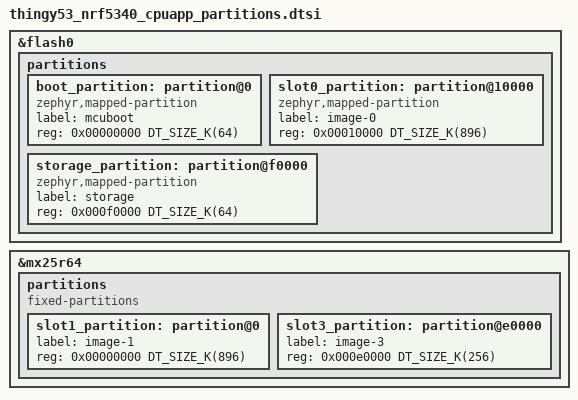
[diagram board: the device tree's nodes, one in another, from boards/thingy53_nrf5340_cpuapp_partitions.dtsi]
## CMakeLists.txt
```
#
# Copyright (c) 2022 Nordic Semiconductor ASA
#
# SPDX-License-Identifier: LicenseRef-Nordic-5-Clause
#

cmake_minimum_required(VERSION 3.20.0)

find_package(Zephyr REQUIRED HINTS $ENV{ZEPHYR_BASE})
project(nrf_wifi_radio_test)

target_sources(app PRIVATE
  src/nrf_wifi_radio_test_main.c
)
```

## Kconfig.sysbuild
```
#
# Copyright (c) 2024 Nordic Semiconductor
#
# SPDX-License-Identifier: LicenseRef-Nordic-5-Clause
#

source "${ZEPHYR_NRF_MODULE_DIR}/samples/wifi/Kconfig.sysbuild.nrf70"

config SUPPORT_NETCORE_PERIPHERAL_RADIO_TEST
	bool
	default y if SOC_SERIES_NRF53 || SOC_SERIES_NRF54

choice NETCORE

config NETCORE_PERIPHERAL_RADIO_TEST
	bool "peripheral_radio_test"
	depends on SUPPORT_NETCORE_PERIPHERAL_RADIO_TEST
	help
	  Include peripheral_radio_test as the netcore image to use

endchoice

config NETCORE_IMAGE_NAME
	default "peripheral_radio_test" if NETCORE_PERIPHERAL_RADIO_TEST

config NETCORE_IMAGE_PATH
	default "$(ZEPHYR_NRF_MODULE_DIR)/samples/peripheral/radio_test/" if NETCORE_PERIPHERAL_RADIO_TEST

source "share/sysbuild/Kconfig"
```

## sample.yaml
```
sample:
  description: Wi-Fi radio test sample application
  name: Wi-Fi radio test
tests:
  sample.nrf7002.radio_test:
    sysbuild: true
    build_only: true
    integration_platforms:
      - nrf7002dk/nrf5340/cpuapp
    platform_allow: nrf7002dk/nrf5340/cpuapp
    tags:
      - ci_build
      - sysbuild
      - ci_samples_wifi
  sample.nrf7001.radio_test:
    sysbuild: true
    build_only: true
    integration_platforms:
      - nrf7002dk/nrf5340/cpuapp/nrf7001
    platform_allow: nrf7002dk/nrf5340/cpuapp/nrf7001
    tags:
      - ci_build
      - sysbuild
      - ci_samples_wifi
    skip: true
  sample.nrf7002.radio_test_combo:
    sysbuild: true
    build_only: true
    extra_args:
      - CONFIG_NRF70_SR_COEX=y
      - CONFIG_NRF70_SR_COEX_RF_SWITCH=y
      - SB_CONFIG_NETCORE_PERIPHERAL_RADIO_TEST=y
    integration_platforms:
      - nrf7002dk/nrf5340/cpuapp
    platform_allow: nrf7002dk/nrf5340/cpuapp
    tags:
      - ci_build
      - sysbuild
      - ci_samples_wifi
  sample.nrf7002_eks.radio_test:
    sysbuild: true
    build_only: true
    extra_args: SHIELD=nrf7002ek
    integration_platforms:
      - nrf5340dk/nrf5340/cpuapp
    platform_allow:
      - nrf5340dk/nrf5340/cpuapp
      - nrf52840dk/nrf52840
    tags:
      - ci_build
      - sysbuild
      - ci_samples_wifi
  sample.nrf7001_eks.radio_test:
    sysbuild: true
    build_only: true
    extra_args: SHIELD=nrf7002ek_nrf7001
    integration_platforms:
      - nrf52840dk/nrf52840
    platform_allow:
      - nrf5340dk/nrf5340/cpuapp
      - nrf52840dk/nrf52840
    tags:
      - ci_build
      - sysbuild
      - ci_samples_wifi
  sample.nrf7000_eks.radio_test:
    sysbuild: true
    build_only: true
    extra_args: SHIELD=nrf7002ek_nrf7000
    integration_platforms:
      - nrf9160dk/nrf9160/ns
    platform_allow: nrf9160dk/nrf9160/ns
    tags:
      - ci_build
      - sysbuild
      - ci_samples_wifi
  sample.nrf7002_eb.thingy53.radio_test:
    sysbuild: true
    build_only: true
    extra_args: multi_domain_SHIELD=nrf7002eb
    integration_platforms:
      - thingy53/nrf5340/cpuapp
    platform_allow: thingy53/nrf5340/cpuapp
    tags:
      - ci_build
      - sysbuild
      - ci_samples_wifi
  sample.thingy91x_nrf7002.radio_test:
    sysbuild: true
    build_only: true
    platform_allow: thingy91x/nrf9151/ns
    tags:
      - ci_build
      - sysbuild
      - ci_samples_wifi
  sample.nrf54h_nrf7002eb.radio_test:
    sysbuild: true
    build_only: true
    extra_args:
      - multi_domain_SHIELD="nrf7002eb_interposer_p1;nrf7002eb"
      - SNIPPET=nrf70-wifi
      - CONFIG_SOC_NRF54H20_CPURAD_ENABLE=y
      - SB_CONFIG_NETCORE_PERIPHERAL_RADIO_TEST=y
    integration_platforms:
      - nrf54h20dk/nrf54h20/cpuapp
    platform_allow:
      - nrf54h20dk/nrf54h20/cpuapp
    tags:
      - ci_build
      - sysbuild
      - ci_samples_wifi
  sample.nrf7120.radio_test:
    sysbuild: true
    build_only: true
    extra_args:
      - SB_CONFIG_WIFI_NRF70=n
    integration_platforms:
      - nrf7120dk/nrf7120/cpuapp
    platform_allow: nrf7120dk/nrf7120/cpuapp
    tags:
      - ci_build
      - sysbuild
      - ci_samples_nrf71_wifi
```

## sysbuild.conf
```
#
# Copyright (c) 2024 Nordic Semiconductor ASA
#
# SPDX-License-Identifier: LicenseRef-Nordic-5-Clause
#

SB_CONFIG_WIFI_NRF70_RADIO_TEST=y
```

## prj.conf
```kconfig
#
# Copyright (c) 2022 Nordic Semiconductor ASA
#
# SPDX-License-Identifier: LicenseRef-Nordic-5-Clause
#
CONFIG_WIFI=y

#CONFIG_INIT_STACKS=y

# Memories
CONFIG_MAIN_STACK_SIZE=5200
CONFIG_SHELL_STACK_SIZE=5200
#64K memory needed for IQ sample captures.
CONFIG_NRF_WIFI_CTRL_HEAP_SIZE=78304

# Debugging
CONFIG_STACK_SENTINEL=y
CONFIG_DEBUG_COREDUMP=y
CONFIG_DEBUG_COREDUMP_BACKEND_LOGGING=y
CONFIG_DEBUG_COREDUMP_MEMORY_DUMP_MIN=y
CONFIG_SHELL_CMDS_RESIZE=n
#CONFIG_DEBUG=y

# Logging
CONFIG_LOG=y
CONFIG_PRINTK=y
CONFIG_SHELL=y
CONFIG_SHELL_GETOPT=y
CONFIG_DEVICE_SHELL=y
CONFIG_POSIX_TIMERS=y
CONFIG_DATE_SHELL=y
CONFIG_LOG_BUFFER_SIZE=4096
CONFIG_SHELL_BACKEND_SERIAL_RX_RING_BUFFER_SIZE=1024
```

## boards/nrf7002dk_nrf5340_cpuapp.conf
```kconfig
# Copyright (c) 2026 Nordic Semiconductor ASA
#
# SPDX-License-Identifier: LicenseRef-Nordic-5-Clause

CONFIG_NRF70_RADIO_TEST=y
CONFIG_NRF70_SR_COEX=y
```

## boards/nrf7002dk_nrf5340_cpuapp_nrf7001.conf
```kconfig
#
# Copyright (c) 2026 Nordic Semiconductor ASA
#
# SPDX-License-Identifier: LicenseRef-Nordic-5-Clause
#

#NRF70 specific configuration
CONFIG_NRF70_RADIO_TEST=y
CONFIG_NRF70_SR_COEX=y
```

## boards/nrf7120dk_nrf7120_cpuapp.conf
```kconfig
# Copyright (c) 2026 Nordic Semiconductor ASA
#
# SPDX-License-Identifier: LicenseRef-Nordic-5-Clause

CONFIG_NRF71_RADIO_TEST=y
CONFIG_NRF71_SR_COEX=y
CONFIG_HEAP_MEM_POOL_SIZE=65536
```

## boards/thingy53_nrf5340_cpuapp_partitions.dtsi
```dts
/*
 * Copyright (c) 2024 Nordic Semiconductor ASA
 *
 * SPDX-License-Identifier: LicenseRef-Nordic-5-Clause
 */

/*
 * Shared flash partition layout for thingy53/nrf5340/cpuapp.
 * Used by the sysbuild mcuboot overlay.
 *
 * Internal flash (flash0):
 *   boot_partition    @ 0x000000  64 KB  MCUboot
 *   slot0_partition   @ 0x010000 896 KB  Image 0 primary
 *   storage_partition @ 0x0f0000  64 KB  Settings
 *
 * External QSPI flash (mx25r64):
 *   slot1_partition   @ 0x000000 896 KB  Image 0 secondary
 *   slot3_partition   @ 0x0e0000 256 KB  Image 1 secondary (network core)
 */

/delete-node/ &boot_partition;
/delete-node/ &slot0_partition;
/delete-node/ &slot1_partition;
/delete-node/ &storage_partition;

&flash0 {
	partitions {
		ranges;
		#address-cells = <1>;
		#size-cells = <1>;

		boot_partition: partition@0 {
			compatible = "zephyr,mapped-partition";
			label = "mcuboot";
			reg = <0x00000000 DT_SIZE_K(64)>;
		};

		slot0_partition: partition@10000 {
			compatible = "zephyr,mapped-partition";
			label = "image-0";
			reg = <0x00010000 DT_SIZE_K(896)>;
		};

		storage_partition: partition@f0000 {
			compatible = "zephyr,mapped-partition";
			label = "storage";
			reg = <0x000f0000 DT_SIZE_K(64)>;
		};
	};
};

&mx25r64 {
	status = "okay";

	partitions {
		compatible = "fixed-partitions";
		#address-cells = <1>;
		#size-cells = <1>;

		slot1_partition: partition@0 {
			label = "image-1";
			reg = <0x00000000 DT_SIZE_K(896)>;
		};

		slot3_partition: partition@e0000 {
			label = "image-3";
			reg = <0x000e0000 DT_SIZE_K(256)>;
		};
	};
};
```

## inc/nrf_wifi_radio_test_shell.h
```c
/*
 * Copyright (c) 2022 Nordic Semiconductor ASA
 *
 * SPDX-License-Identifier: LicenseRef-Nordic-5-Clause
 */

/* @file
 * @brief nRF Wi-Fi radio-test mode shell module
 */

#include <zephyr/kernel.h>
#include <stdio.h>
#include <stdlib.h>
#include <zephyr/shell/shell.h>
#include <zephyr/init.h>
#include <ctype.h>
#ifndef CONFIG_NRF71_RADIO_TEST
#include <host_rpu_sys_if.h>
#endif
#include <radio_test/fmac_structs.h>
#include <zephyr/drivers/wifi/nrf_wifi/bus/rpu_hw_if.h>

enum nrf_wifi_frequency_bands {
	NRF_WIFI_FREQ_BAND_2_4_GHZ = 0,
	NRF_WIFI_FREQ_BAND_5_GHZ,
	NRF_WIFI_FREQ_BAND_6_GHZ,
};

/* RX capture display constants */
#define SAMPLES_PER_LINE 16
#define BYTES_PER_SAMPLE 3
#define BYTES_PER_LINE 48

struct nrf_wifi_ctx_zep_rt {
	struct nrf_wifi_fmac_priv *fmac_priv;
	struct rpu_conf_params conf_params;
};
```

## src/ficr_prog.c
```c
/*
 * Copyright (c) 2024 Nordic Semiconductor ASA
 *
 * SPDX-License-Identifier: LicenseRef-Nordic-5-Clause
 */

/* @file
 * @brief NRF Wi-Fi radio FICR programming functions
 */

#include <zephyr/logging/log.h>
#include <zephyr/kernel.h>
#include <zephyr/drivers/wifi/nrf_wifi/bus/rpu_hw_if.h>

#include "common/rpu_if.h"
#include "ficr_prog.h"


LOG_MODULE_DECLARE(otp_prog, CONFIG_WIFI_LOG_LEVEL);

static void write_word(unsigned int addr, unsigned int data)
{
	rpu_write(addr, &data, 4);
}

static void read_word(unsigned int addr, unsigned int *data)
{
	rpu_read(addr, data, 4);
}

unsigned int check_protection(unsigned int *buff, unsigned int off1, unsigned int off2,
		    unsigned int off3, unsigned int off4)
{
	if ((buff[off1] == OTP_PROGRAMMED) &&
		(buff[off2] == OTP_PROGRAMMED)  &&
		(buff[off3] == OTP_PROGRAMMED) &&
		(buff[off4] == OTP_PROGRAMMED)) {
		return OTP_PROGRAMMED;
	} else if ((buff[off1] == OTP_FRESH_FROM_FAB) &&
		(buff[off2] == OTP_FRESH_FROM_FAB) &&
		(buff[off3] == OTP_FRESH_FROM_FAB) &&
		(buff[off4] == OTP_FRESH_FROM_FAB)) {
		return OTP_FRESH_FROM_FAB;
	} else if ((buff[off1] == OTP_ENABLE_PATTERN) &&
		(buff[off2] == OTP_ENABLE_PATTERN) &&
		(buff[off3] == OTP_ENABLE_PATTERN) &&
		(buff[off4] == OTP_ENABLE_PATTERN)) {
		return OTP_ENABLE_PATTERN;
	} else {
		return OTP_INVALID;
	}
}

static void set_otp_timing_reg_40mhz(void)
{
	write_word(OTP_TIMING_REG1_ADDR, OTP_TIMING_REG1_VAL);
	write_word(OTP_TIMING_REG2_ADDR, OTP_TIMING_REG2_VAL);
}

static int poll_otp_ready(void)
{
	int otp_mem_status = 0;
	int poll = 0;

	while (poll != 100) {
		read_word(OTP_POLL_ADDR, &otp_mem_status);

		if ((otp_mem_status & OTP_READY) == OTP_READY) {
			return 0;
		}
		poll++;
	}
	LOG_ERR("OTP is not ready");
	return -ENOEXEC;
}

static int req_otp_standby_mode(void)
{
	write_word(OTP_RWSBMODE_ADDR, 0x0);
	return poll_otp_ready();
}

static int otp_wr_voltage_2v5(void)
{
	int err;

	err = req_otp_standby_mode();

	if (err) {
		LOG_ERR("Failed Setting OTP voltage IOVDD to 2.5V");
		return -ENOEXEC;
	}
	write_word(OTP_VOLTCTRL_ADDR, OTP_VOLTCTRL_2V5);
	return 0;
}

static int poll_otp_read_valid(void)
{
	int otp_mem_status = 0;
	int poll = 0;

	while (poll < 100) {
		read_word(OTP_POLL_ADDR, &otp_mem_status);

		if ((otp_mem_status & OTP_READ_VALID) == OTP_READ_VALID) {
			return 0;
		}
		poll++;
	}
	LOG_ERR("%s: OTP read failed", __func__);
	return -ENOEXEC;
}

static int poll_otp_wrdone(void)
{
	int otp_mem_status = 0;
	int poll = 0;

	while (poll < 100) {
		read_word(OTP_POLL_ADDR, &otp_mem_status);

		if ((otp_mem_status & OTP_WR_DONE) == OTP_WR_DONE) {
			return 0;
		}
		poll++;
	}
	LOG_ERR("%s: OTP write done failed", __func__);
	return -ENOEXEC;
}

static int req_otp_read_mode(void)
{
	write_word(OTP_RWSBMODE_ADDR, OTP_READ_MODE);
	return poll_otp_ready();
}

static int req_otp_byte_write_mode(void)
{
	write_word(OTP_RWSBMODE_ADDR, OTP_BYTE_WRITE_MODE);
	return poll_otp_ready();
}

static unsigned int read_otp_location(unsigned int offset, unsigned int *read_val)
{
	int err;

	write_word(OTP_RDENABLE_ADDR,  offset);
	err = poll_otp_read_valid();
	if (err) {
		LOG_ERR("OTP read failed");
		return err;
	}
	read_word(OTP_READREG_ADDR, read_val);

	return 0;
}

static int  write_otp_location(unsigned int otp_location_offset, unsigned int otp_data)
{
	write_word(OTP_WRENABLE_ADDR,  otp_location_offset);
	write_word(OTP_WRITEREG_ADDR,  otp_data);

	return poll_otp_wrdone();
}

static int otp_rd_voltage_1v8(void)
{
	int err;

	err = req_otp_standby_mode();
	if (err) {
		LOG_ERR("error in %s", __func__);
		return err;
	}
	write_word(OTP_VOLTCTRL_ADDR, OTP_VOLTCTRL_1V8);

	return 0;
}

static int update_mac_addr(unsigned int index, unsigned int *write_val)
{
	int ret = 0;

	for (int i = 0; i < 2; i++) {
		ret = write_otp_location(MAC0_ADDR + 2 * index + i, write_val[i]);
		if (ret == -ENOEXEC) {
			LOG_ERR("FICR: Failed to update MAC ADDR%d", index);
			break;
		}
		LOG_INF("mac addr %d : Reg%d (0x%x) = 0x%04x",
					index, (i+1), (MAC0_ADDR + i) << 2, write_val[i]);
	}
	return ret;
}

int write_otp_memory(unsigned int otp_addr, unsigned int *write_val)
{
	int err = 0;
	int	mask_val;
	int ret = 0;
	int retrim_loc = 0;

	err = poll_otp_ready();
	if (err) {
		LOG_ERR("err in otp ready poll");
		return err;
	}

	set_otp_timing_reg_40mhz();

	err = otp_wr_voltage_2v5();
	if (err) {
		LOG_ERR("error in write_voltage 2v5");
		goto _exit_otp_write;
	}

	err = req_otp_byte_write_mode();
	if (err) {
		LOG_ERR("error in OTP byte write mode");
		goto _exit_otp_write;
	}

	switch (otp_addr) {
	case REGION_PROTECT:
		write_otp_location(REGION_PROTECT, write_val[0]);
		write_otp_location(REGION_PROTECT+1, write_val[0]);
		write_otp_location(REGION_PROTECT+2, write_val[0]);
		write_otp_location(REGION_PROTECT+3, write_val[0]);

		LOG_INF("Written REGION_PROTECT0 (0x%x) : 0x%04x",
						(REGION_PROTECT << 2), write_val[0]);
		LOG_INF("Written REGION_PROTECT1 (0x%x) : 0x%04x",
						(REGION_PROTECT+1) << 2, write_val[0]);
		LOG_INF("Written REGION_PROTECT2 (0x%x) : 0x%04x",
						(REGION_PROTECT+2) << 2, write_val[0]);
		LOG_INF("Written REGION_PROTECT3 (0x%x) : 0x%04x",
						(REGION_PROTECT+3) << 2, write_val[0]);
		break;
	case QSPI_KEY:
		mask_val = QSPI_KEY_FLAG_MASK;
		for (int i = 0; i < QSPI_KEY_LENGTH_BYTES / 4; i++) {
			ret = write_otp_location(QSPI_KEY + i, write_val[i]);
			if (ret == -ENOEXEC) {
				LOG_ERR("FICR: Failed to write QSPI key offset-%d", QSPI_KEY + i);
				goto _exit_otp_write;
			}
			LOG_INF("Written QSPI_KEY0 (0x%x) : 0x%04x",
						(QSPI_KEY + i) << 2, write_val[i]);
		}
		write_otp_location(REGION_DEFAULTS, mask_val);
		LOG_INF("Written REGION_DEFAULTS (0x%x) : 0x%04x",
						(REGION_DEFAULTS) << 2, mask_val);
		break;
	case MAC0_ADDR:
		mask_val = MAC0_ADDR_FLAG_MASK;
		ret = update_mac_addr(0, write_val);
		if (ret == -ENOEXEC) {
			goto _exit_otp_write;
		}

		write_otp_location(REGION_DEFAULTS, mask_val);
		LOG_INF("Written MAC address 0");
		LOG_INF("Written REGION_DEFAULTS (0x%x) : 0x%04x",
						(REGION_DEFAULTS) << 2, mask_val);
		break;
	case MAC1_ADDR:
		mask_val = MAC1_ADDR_FLAG_MASK;
		ret = update_mac_addr(1, write_val);
		if (ret == -ENOEXEC) {
			goto _exit_otp_write;
		}
		write_otp_location(REGION_DEFAULTS, mask_val);
		LOG_INF("Written MAC address 1");
		LOG_INF("Written REGION_DEFAULTS (0x%x) : 0x%04x",
						(REGION_DEFAULTS) << 2, mask_val);
		break;
	case CALIB_XO:
		mask_val = CALIB_XO_FLAG_MASK;
		ret = write_otp_location(CALIB_XO, write_val[0]);

		if (ret == -ENOEXEC) {
			LOG_ERR("XO_Update Exception");
			goto _exit_otp_write;
		} else {
			write_otp_location(REGION_DEFAULTS, mask_val);

			LOG_INF("Written CALIB_XO (0x%x) to 0x%04x",
						CALIB_XO << 2, write_val[0]);
			LOG_INF("Written REGION_DEFAULTS (0x%x) : 0x%04x",
						(REGION_DEFAULTS) << 2, mask_val);
		}
		break;
	case PRODRETEST_PROGVERSION:
		ret = write_otp_location(PRODRETEST_PROGVERSION, *write_val);

		if (ret == -ENOEXEC) {
			LOG_ERR("PRODRETEST.PROGVERSION_Update Exception");
			goto _exit_otp_write;
		} else {
			LOG_INF("Written PRODRETEST.PROGVERSION 0x%04x", *write_val);
		}
		break;
	case PRODRETEST_TRIM0:
	case PRODRETEST_TRIM1:
	case PRODRETEST_TRIM2:
	case PRODRETEST_TRIM3:
	case PRODRETEST_TRIM4:
	case PRODRETEST_TRIM5:
	case PRODRETEST_TRIM6:
	case PRODRETEST_TRIM7:
	case PRODRETEST_TRIM8:
	case PRODRETEST_TRIM9:
	case PRODRETEST_TRIM10:
	case PRODRETEST_TRIM11:
	case PRODRETEST_TRIM12:
	case PRODRETEST_TRIM13:
	case PRODRETEST_TRIM14:
		retrim_loc = otp_addr - PRODRETEST_TRIM0;
		ret = write_otp_location(otp_addr, *write_val);

		if (ret == -ENOEXEC) {
			LOG_ERR("PRODRETEST.TRIM_Update Exception");
			goto _exit_otp_write;
		} else {
			LOG_INF("Written PRODRETEST.TRIM%d 0x%04x",
						retrim_loc, *write_val);
		}
		break;
	case REGION_DEFAULTS:
		write_otp_location(REGION_DEFAULTS, write_val[0]);

		LOG_INF("Written REGION_DEFAULTS (0x%x) to 0x%04x",
						REGION_DEFAULTS << 2, write_val[0]);
		break;
	default:
		LOG_ERR("unknown field received: %d", otp_addr);

	}
	return ret;

_exit_otp_write:
	err  = req_otp_standby_mode();
	err |= otp_rd_voltage_1v8();
	return err;
}

int read_otp_memory(unsigned int otp_addr, unsigned int *read_val, int len)
{
	int	err;

	err = poll_otp_ready();
	if (err) {
		LOG_ERR("err in otp ready poll");
		return -ENOEXEC;
	}

	set_otp_timing_reg_40mhz();

	err = otp_rd_voltage_1v8();
	if (err) {
		LOG_ERR("error in read_voltage 1v8");
		return -ENOEXEC;
	}

	err = req_otp_read_mode();
	if (err) {
		LOG_ERR("error in req_otp_read_mode()");
		return -ENOEXEC;
	}

	for (int i = 0; i < len; i++) {
		read_otp_location(otp_addr + i, &read_val[i]);
	}

	return req_otp_standby_mode();
}
```

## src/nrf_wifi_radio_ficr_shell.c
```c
/*
 * Copyright (c) 2022 Nordic Semiconductor ASA
 *
 * SPDX-License-Identifier: LicenseRef-Nordic-5-Clause
 */

/* @file
 * @brief NRF Wi-Fi radio test shell module
 */

#include <zephyr/logging/log.h>
#include <fmac_main.h>
#include <util.h>
#include <nrf_wifi_radio_test_shell.h>
#include "ficr_prog.h"

#include "common/fmac_api_common.h"

extern struct nrf_wifi_drv_priv_zep rpu_drv_priv_zep;
static struct nrf_wifi_ctx_zep *ctx = &rpu_drv_priv_zep.rpu_ctx_zep;

LOG_MODULE_REGISTER(otp_prog, CONFIG_WIFI_LOG_LEVEL);

static void disp_location_status(const struct shell *shell, char *region, unsigned int ret)
{
	switch (ret) {

	case OTP_PROGRAMMED:
		shell_fprintf(shell, SHELL_INFO, "%s Region is locked!!!\n", region);
		break;
	case OTP_ENABLE_PATTERN:
		shell_fprintf(shell, SHELL_INFO, "%s Region is open for R/W\n", region);
		break;
	case OTP_FRESH_FROM_FAB:
		shell_fprintf(shell, SHELL_INFO,
				"%s Region is unprogrammed - program to enable R/W\n", region);
		break;
	default:
		shell_fprintf(shell, SHELL_ERROR, "%s Region is in invalid state\n", region);
		break;
	}
	shell_fprintf(shell, SHELL_INFO, "\n");
}

static void disp_fields_status(const struct shell *shell, unsigned int flags)
{
	if (flags & (~QSPI_KEY_FLAG_MASK)) {
		shell_fprintf(shell, SHELL_INFO, "QSPI Keys are not programmed in OTP\n");
	} else {
		shell_fprintf(shell, SHELL_INFO, "QSPI Keys are programmed in OTP\n");
	}

	if (flags & (~MAC0_ADDR_FLAG_MASK)) {
		shell_fprintf(shell, SHELL_INFO, "MAC0 Address are not programmed in OTP\n");
	} else {
		shell_fprintf(shell, SHELL_INFO, "MAC0 Address is programmed in OTP\n");
	}

	if (flags & (~MAC1_ADDR_FLAG_MASK)) {
		shell_fprintf(shell, SHELL_INFO, "MAC1 Address are not programmed in OTP\n");
	} else {
		shell_fprintf(shell, SHELL_INFO, "MAC1 Address is programmed in OTP\n");
	}

	if (flags & (~CALIB_XO_FLAG_MASK)) {
		shell_fprintf(shell, SHELL_INFO, "CALIB_XO is not programmed in OTP\n");
	} else {
		shell_fprintf(shell, SHELL_INFO, "CALIB_XO is programmed in OTP\n");
	}
}


static int nrf_wifi_radio_test_otp_get_status(const struct shell *shell,
					size_t argc,
					char  *argv[])
{
	unsigned int ret, err;
	unsigned int val[OTP_MAX_WORD_LEN];

	/* read all the OTP memory */
	err = read_otp_memory(0, &val[0], OTP_MAX_WORD_LEN);
	if (err) {
		shell_fprintf(shell, SHELL_ERROR, "FAILED reading otp memory......\n");
		return -ENOEXEC;
	}

	shell_fprintf(shell, SHELL_INFO, "Checking OTP PROTECT Region......\n");
	ret = check_protection(&val[0], REGION_PROTECT, REGION_PROTECT + 1,
							REGION_PROTECT + 2, REGION_PROTECT + 3);

	disp_location_status(shell, "OTP", ret);
	disp_fields_status(shell, val[REGION_DEFAULTS]);

	return 0;
}

static int nrf_wifi_radio_test_otp_read_params(const struct shell *shell,
					size_t argc,
					char  *argv[])
{
	unsigned int val[OTP_MAX_WORD_LEN];
	unsigned int ret, err;

	err = read_otp_memory(0, &val[0], OTP_MAX_WORD_LEN);
	if (err) {
		shell_fprintf(shell, SHELL_ERROR, "FAILED reading otp memory......\n");
		return -ENOEXEC;
	}

	ret = check_protection(&val[0], REGION_PROTECT + 0, REGION_PROTECT + 1,
							REGION_PROTECT + 2, REGION_PROTECT + 3);
	disp_location_status(shell, "OTP", ret);

	shell_fprintf(shell, SHELL_INFO, "PRODTEST.FT.PROGVERSION = 0x%08x\n",
		val[PRODTEST_FT_PROGVERSION]);
	shell_fprintf(shell, SHELL_INFO, "\n");

	shell_fprintf(shell, SHELL_INFO, "PRODTEST.TRIM0 = 0x%08x\n", val[PRODTEST_TRIM0]);
	shell_fprintf(shell, SHELL_INFO, "PRODTEST.TRIM1 = 0x%08x\n", val[PRODTEST_TRIM1]);
	shell_fprintf(shell, SHELL_INFO, "PRODTEST.TRIM2 = 0x%08x\n", val[PRODTEST_TRIM2]);
	shell_fprintf(shell, SHELL_INFO, "PRODTEST.TRIM3 = 0x%08x\n", val[PRODTEST_TRIM3]);
	shell_fprintf(shell, SHELL_INFO, "PRODTEST.TRIM4 = 0x%08x\n", val[PRODTEST_TRIM4]);
	shell_fprintf(shell, SHELL_INFO, "PRODTEST.TRIM5 = 0x%08x\n", val[PRODTEST_TRIM5]);
	shell_fprintf(shell, SHELL_INFO, "PRODTEST.TRIM6 = 0x%08x\n", val[PRODTEST_TRIM6]);
	shell_fprintf(shell, SHELL_INFO, "PRODTEST.TRIM7 = 0x%08x\n", val[PRODTEST_TRIM7]);
	shell_fprintf(shell, SHELL_INFO, "PRODTEST.TRIM8 = 0x%08x\n", val[PRODTEST_TRIM8]);
	shell_fprintf(shell, SHELL_INFO, "PRODTEST.TRIM9 = 0x%08x\n", val[PRODTEST_TRIM9]);
	shell_fprintf(shell, SHELL_INFO, "PRODTEST.TRIM10 = 0x%08x\n",
		val[PRODTEST_TRIM10]);
	shell_fprintf(shell, SHELL_INFO, "PRODTEST.TRIM11 = 0x%08x\n",
		val[PRODTEST_TRIM11]);
	shell_fprintf(shell, SHELL_INFO, "PRODTEST.TRIM12 = 0x%08x\n",
		val[PRODTEST_TRIM12]);
	shell_fprintf(shell, SHELL_INFO, "PRODTEST.TRIM13 = 0x%08x\n",
		val[PRODTEST_TRIM13]);
	shell_fprintf(shell, SHELL_INFO, "PRODTEST.TRIM14 = 0x%08x\n",
		val[PRODTEST_TRIM14]);
	shell_fprintf(shell, SHELL_INFO, "\n");

	shell_fprintf(shell, SHELL_INFO, "INFO.PART = 0x%08x\n", val[INFO_PART]);
	shell_fprintf(shell, SHELL_INFO, "INFO.VARIANT = 0x%08x\n", val[INFO_VARIANT]);
	shell_fprintf(shell, SHELL_INFO, "\n");

	shell_fprintf(shell, SHELL_INFO, "INFO.UUID0 = 0x%08x\n", val[INFO_UUID + 0]);
	shell_fprintf(shell, SHELL_INFO, "INFO.UUID1 = 0x%08x\n", val[INFO_UUID + 1]);
	shell_fprintf(shell, SHELL_INFO, "INFO.UUID2 = 0x%08x\n", val[INFO_UUID + 2]);
	shell_fprintf(shell, SHELL_INFO, "INFO.UUID3 = 0x%08x\n", val[INFO_UUID + 3]);
	shell_fprintf(shell, SHELL_INFO, "\n");

	shell_fprintf(shell, SHELL_INFO, "REGION.PROTECT0 = 0x%08x\n", val[REGION_PROTECT + 0]);
	shell_fprintf(shell, SHELL_INFO, "REGION.PROTECT1 = 0x%08x\n", val[REGION_PROTECT + 1]);
	shell_fprintf(shell, SHELL_INFO, "REGION.PROTECT2 = 0x%08x\n", val[REGION_PROTECT + 2]);
	shell_fprintf(shell, SHELL_INFO, "REGION.PROTECT3 = 0x%08x\n", val[REGION_PROTECT + 3]);
	shell_fprintf(shell, SHELL_INFO, "\n");

	if (val[REGION_PROTECT + 0] != OTP_FRESH_FROM_FAB) {
		shell_fprintf(shell, SHELL_INFO, "MAC0.ADDRESS0 = 0x%08x\n", val[MAC0_ADDR]);
		shell_fprintf(shell, SHELL_INFO, "MAC0.ADDRESS1 = 0x%08x\n", val[MAC0_ADDR + 1]);
		shell_fprintf(shell, SHELL_INFO, "MAC0.ADDRESS = %02x:%02x:%02x:%02x:%02x:%02x\n",
			(uint8_t)(val[MAC0_ADDR]), (uint8_t)(val[MAC0_ADDR] >> 8),
			(uint8_t)(val[MAC0_ADDR] >> 16), (uint8_t)(val[MAC0_ADDR] >> 24),
			(uint8_t)(val[MAC0_ADDR + 1]), (uint8_t)(val[MAC0_ADDR + 1] >> 8));
		shell_fprintf(shell, SHELL_INFO, "\n");

		shell_fprintf(shell, SHELL_INFO, "MAC1.ADDRESS0 = 0x%08x\n", val[MAC1_ADDR]);
		shell_fprintf(shell, SHELL_INFO, "MAC1.ADDRESS1 = 0x%08x\n", val[MAC1_ADDR + 1]);
		shell_fprintf(shell, SHELL_INFO, "MAC1.ADDRESS = %02x:%02x:%02x:%02x:%02x:%02x\n",
			(uint8_t)(val[MAC1_ADDR]), (uint8_t)(val[MAC1_ADDR] >> 8),
			(uint8_t)(val[MAC1_ADDR] >> 16), (uint8_t)(val[MAC1_ADDR] >> 24),
			(uint8_t)(val[MAC1_ADDR + 1]), (uint8_t)(val[MAC1_ADDR + 1] >> 8));
		shell_fprintf(shell, SHELL_INFO, "\n");

		shell_fprintf(shell, SHELL_INFO, "CALIB.XO = 0x%02x\n", val[CALIB_XO] & 0xFF);

		shell_fprintf(shell, SHELL_INFO, "REGION_DEFAULTS = 0x%08x\n",
			val[REGION_DEFAULTS]);
		shell_fprintf(shell, SHELL_INFO, "\n");
	}
	return 0;
}

static int nrf_wifi_radio_test_otp_read_retrim_version(const struct shell *shell,
					size_t argc,
					char  *argv[])
{
	unsigned int val[1];
	unsigned int err;

	err = read_otp_memory(REGION_PROTECT, &val[0], 1);
	if (err) {
		shell_fprintf(shell, SHELL_ERROR, "FAILED reading otp memory......\n");
		return -ENOEXEC;
	}

	if (val[0] == OTP_FRESH_FROM_FAB) {
		shell_fprintf(shell, SHELL_ERROR,
				"Region is unprogrammed - program to enable R/W\n");
	} else {
		err = read_otp_memory(PRODRETEST_PROGVERSION, &val[0], 1);
		shell_fprintf(shell, SHELL_INFO, "\nPRODRETEST.PROGVERSION = 0x%08x\n",
		val[0]);
		shell_fprintf(shell, SHELL_INFO, "\n");
	}
	return 0;
}

static int nrf_wifi_radio_test_otp_read_retrim_params(const struct shell *shell,
					size_t argc,
					char  *argv[])
{
	unsigned int val[RETRIM_LEN];
	unsigned int err;

	err = read_otp_memory(REGION_PROTECT, val, 1);
	if (err) {
		shell_fprintf(shell, SHELL_ERROR, "FAILED reading otp memory......\n");
		return -ENOEXEC;
	}

	if (val[0] == OTP_FRESH_FROM_FAB) {
		shell_fprintf(shell, SHELL_ERROR,
				"Region is unprogrammed - program to enable R/W\n");
	} else {
		shell_fprintf(shell, SHELL_INFO, "\n");
		err = read_otp_memory(PRODRETEST_TRIM0, val, RETRIM_LEN);
		for (int i = 0; i < RETRIM_LEN; i++) {
			shell_fprintf(shell, SHELL_INFO, "PRODRETEST.TRIM%d = 0x%08x\n", i, val[i]);
		}
		shell_fprintf(shell, SHELL_INFO, "\n");
	}

	return 0;
}

static int nrf_wifi_radio_test_otp_write_params(const struct shell *shell,
					size_t argc,
					char  *argv[])
{
	unsigned int field;
	unsigned int write_val[20];
	unsigned int val[OTP_MAX_WORD_LEN];
	unsigned int ret, err;
	int status = 0;

	if (argc < 2) {
		shell_fprintf(shell, SHELL_ERROR, "invalid # of args : %d\n", argc);
		return -ENOEXEC;
	}

	field  = strtoul(argv[1], NULL, 0);
	/* Align to 32-bit word address */
	field >>= 2;

	if (field < REGION_PROTECT) {
		shell_fprintf(shell, SHELL_ERROR, "INVALID Address 0x%x......\n", field << 2);
		return -ENOEXEC;
	}

	if ((field >= PRODRETEST_PROGVERSION) && (field <= PRODRETEST_TRIM14)) {
		shell_fprintf(shell, SHELL_ERROR, "INVALID Address 0x%x......\n", field << 2);
		return -ENOEXEC;
	}

	err = read_otp_memory(REGION_PROTECT, &val[REGION_PROTECT], 4);
	if (err) {
		shell_fprintf(shell, SHELL_ERROR, "FAILED reading otp memory......\n");
		return -ENOEXEC;
	}

	ret = check_protection(&val[0], REGION_PROTECT, REGION_PROTECT + 1,
						REGION_PROTECT + 2, REGION_PROTECT + 3);
	disp_location_status(shell, "OTP", ret);
	if (ret != OTP_ENABLE_PATTERN && ret != OTP_FRESH_FROM_FAB) {
		shell_fprintf(shell, SHELL_ERROR, "USER Region is not Writeable\n");
		return -ENOEXEC;
	}

	switch (field) {
	case REGION_PROTECT:
		if (argc != 3) {
			shell_fprintf(shell, SHELL_ERROR,
					"invalid # of args for REGION_PROTECT (expected 3) : %d\n",
					argc);
			return -ENOEXEC;
		}
		write_val[0]  = strtoul(argv[2], NULL, 0);
		/* All consecutive 4 words of the REGION_PROTECT are written */
		write_otp_memory(REGION_PROTECT, &write_val[0]);
		break;
	case MAC0_ADDR:
	case MAC1_ADDR:
		struct nrf_wifi_fmac_dev_ctx *fmac_dev_ctx = ctx->rpu_ctx;

		if (!fmac_dev_ctx) {
			shell_fprintf(shell, SHELL_ERROR, "Driver not initialized\n");
			return -ENOEXEC;
		}

		if (argc != 4) {
			shell_fprintf(shell, SHELL_ERROR,
				   "invalid # of args for MAC ADDR write (expected 4) : %d\n",
					argc);
			return -ENOEXEC;
		}
		write_val[0] = strtoul(argv[2], NULL, 0);
		write_val[1] = strtoul(argv[3], NULL, 0) & 0xFFFF;

		if (!nrf_wifi_utils_is_mac_addr_valid((const char *)&write_val[0])) {
			shell_fprintf(shell,
				      SHELL_ERROR,
				      "Invalid MAC address. MAC address cannot be all 0's, broadcast or multicast address\n");
			return -ENOEXEC;
		}

		status = write_otp_memory(field, &write_val[0]);
		break;
	case CALIB_XO:
	case REGION_DEFAULTS:
		if (argc != 3) {
			shell_fprintf(shell, SHELL_ERROR,
			  "invalid # of args for field %d (expected 3) : %d\n", field, argc);
			return -ENOEXEC;
		}
		write_val[0]  = strtoul(argv[2], NULL, 0);
		status = write_otp_memory(field, &write_val[0]);
		break;
	case QSPI_KEY:
		if (argc != 6) {
			shell_fprintf(shell, SHELL_ERROR,
					"invalid # of args for QSPI_KEY (expected 6) : %d\n", argc);
			return -ENOEXEC;
		}
		write_val[0]  = strtoul(argv[2], NULL, 0);
		write_val[1]  = strtoul(argv[3], NULL, 0);
		write_val[2]  = strtoul(argv[4], NULL, 0);
		write_val[3]  = strtoul(argv[5], NULL, 0);
		/* All consecutive 4 words of the qspi keys are written now */
		status = write_otp_memory(QSPI_KEY, &write_val[0]);
		break;
	default:
		shell_fprintf(shell, SHELL_ERROR, "unsupported field %d\n", field);
		return -ENOEXEC;
	}

	if (!status) {
		shell_fprintf(shell, SHELL_INFO, "Finished Writing OTP params\n");
	}

	return 0;
}

static int nrf_wifi_radio_test_otp_write_retrim_version(const struct shell *shell,
					size_t argc,
					char  *argv[])
{
	unsigned int field;
	unsigned int write_val;
	unsigned int val[OTP_MAX_WORD_LEN];
	unsigned int ret, err;
	int status = 0;

	field = PRODRETEST_PROGVERSION;

	if (argc != 2) {
		shell_fprintf(shell, SHELL_ERROR,
		  "invalid # of args for field %d (expected 2) : %d\n", field, argc);
		return -ENOEXEC;
	}

	err = read_otp_memory(REGION_PROTECT, &val[REGION_PROTECT], 4);
	if (err) {
		shell_fprintf(shell, SHELL_ERROR, "FAILED reading otp memory......\n");
		return -ENOEXEC;
	}

	ret = check_protection(&val[0], REGION_PROTECT, REGION_PROTECT + 1,
						REGION_PROTECT + 2, REGION_PROTECT + 3);
	disp_location_status(shell, "OTP", ret);
	if (ret != OTP_ENABLE_PATTERN && ret != OTP_FRESH_FROM_FAB) {
		shell_fprintf(shell, SHELL_ERROR, "USER Region is not Writeable\n");
		return -ENOEXEC;
	}

	write_val  = strtoul(argv[1], NULL, 0);
	status = write_otp_memory(field, &write_val);

	if (!status) {
		shell_fprintf(shell, SHELL_INFO, "Finished Writing Retrim version\n");
	}

	return 0;
}

static int nrf_wifi_radio_test_otp_write_retrim_params(const struct shell *shell,
					size_t argc,
					char  *argv[])
{
	unsigned int index;
	unsigned int field;
	unsigned int write_val;
	unsigned int val[OTP_MAX_WORD_LEN];
	unsigned int ret, err;
	int status = 0;

	index = strtoul(argv[1], NULL, 0);
	field = index+PRODRETEST_TRIM0;

	if ((field < PRODRETEST_TRIM0) || (field > PRODRETEST_TRIM14)) {
		shell_fprintf(shell, SHELL_ERROR, "INVALID Index %d......\n", index);
		return -ENOEXEC;
	}

	err = read_otp_memory(REGION_PROTECT, &val[REGION_PROTECT], 4);
	if (err) {
		shell_fprintf(shell, SHELL_ERROR, "FAILED reading otp memory......\n");
		return -ENOEXEC;
	}

	ret = check_protection(&val[0], REGION_PROTECT, REGION_PROTECT + 1,
						REGION_PROTECT + 2, REGION_PROTECT + 3);
	disp_location_status(shell, "OTP", ret);
	if (ret != OTP_ENABLE_PATTERN && ret != OTP_FRESH_FROM_FAB) {
		shell_fprintf(shell, SHELL_ERROR, "USER Region is not Writeable\n");
		return -ENOEXEC;
	}

	switch (field) {
	case PRODRETEST_TRIM0:
	case PRODRETEST_TRIM1:
	case PRODRETEST_TRIM2:
	case PRODRETEST_TRIM3:
	case PRODRETEST_TRIM4:
	case PRODRETEST_TRIM5:
	case PRODRETEST_TRIM6:
	case PRODRETEST_TRIM7:
	case PRODRETEST_TRIM8:
	case PRODRETEST_TRIM9:
	case PRODRETEST_TRIM10:
	case PRODRETEST_TRIM11:
	case PRODRETEST_TRIM12:
	case PRODRETEST_TRIM13:
	case PRODRETEST_TRIM14:
		if (argc != 3) {
			shell_fprintf(shell, SHELL_ERROR,
				"invalid # of args for field %d (expected 3) : %d\n", field, argc);
			return -ENOEXEC;
		}
		write_val  = strtoul(argv[2], NULL, 0);
		status = write_otp_memory(field, &write_val);
		break;
	default:
		shell_fprintf(shell, SHELL_ERROR, "unsupported field %d\n", field);
		return -ENOEXEC;
	}

	if (!status) {
		shell_fprintf(shell, SHELL_INFO, "Finished Writing Retrim param\n");
	}

	return 0;
}

SHELL_STATIC_SUBCMD_SET_CREATE(
	nrf_wifi_radio_otp_subcmds,
	SHELL_CMD_ARG(otp_get_status,
			  NULL,
			  "Read OTP status",
			  nrf_wifi_radio_test_otp_get_status,
			  1,
			  0),
	SHELL_CMD_ARG(otp_read_params,
			  NULL,
			  "Read User region status and information on programmed fields",
			  nrf_wifi_radio_test_otp_read_params,
			  1,
			  0),
	SHELL_CMD_ARG(otp_read_retrim_version,
			  NULL,
			  "Read Retrim Version",
			  nrf_wifi_radio_test_otp_read_retrim_version,
			  1,
			  0),
	SHELL_CMD_ARG(otp_read_retrim_params,
			  NULL,
			  "Read Retrim Params",
			  nrf_wifi_radio_test_otp_read_retrim_params,
			  1,
			  0),
	SHELL_CMD_ARG(otp_write_params,
			  NULL,
			  "Write OTP Params\n"
			  "otp_write_params <addr offset> [arg1] [arg2]...[argN]",
			  nrf_wifi_radio_test_otp_write_params,
			  2,
			  16),
	SHELL_CMD_ARG(otp_write_retrim_version,
			  NULL,
			  "Write OTP Retrim Version\n"
			  "otp_write_retrim_version <retrim version>",
			  nrf_wifi_radio_test_otp_write_retrim_version,
			  2,
			  0),
	SHELL_CMD_ARG(otp_write_retrim_params,
			  NULL,
			  "Write OTP Retrim Params\n"
			  "otp_write_params <retrim index> [retrim data]",
			  nrf_wifi_radio_test_otp_write_retrim_params,
			  3,
			  0),
	SHELL_SUBCMD_SET_END);


SHELL_CMD_REGISTER(wifi_radio_ficr_prog,
		   &nrf_wifi_radio_otp_subcmds,
		   "nRF Wi-Fi radio FICR commands",
		   NULL);


static int nrf_wifi_radio_otp_shell_init(void)
{

	return 0;
}


SYS_INIT(nrf_wifi_radio_otp_shell_init,
	 APPLICATION,
	 CONFIG_APPLICATION_INIT_PRIORITY);
```

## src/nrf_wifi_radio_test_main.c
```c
/*
 * Copyright (c) 2022 Nordic Semiconductor ASA
 *
 * SPDX-License-Identifier: LicenseRef-Nordic-5-Clause
 */

#include <zephyr/kernel.h>

int main(void)
{
	return 0;
}
```
